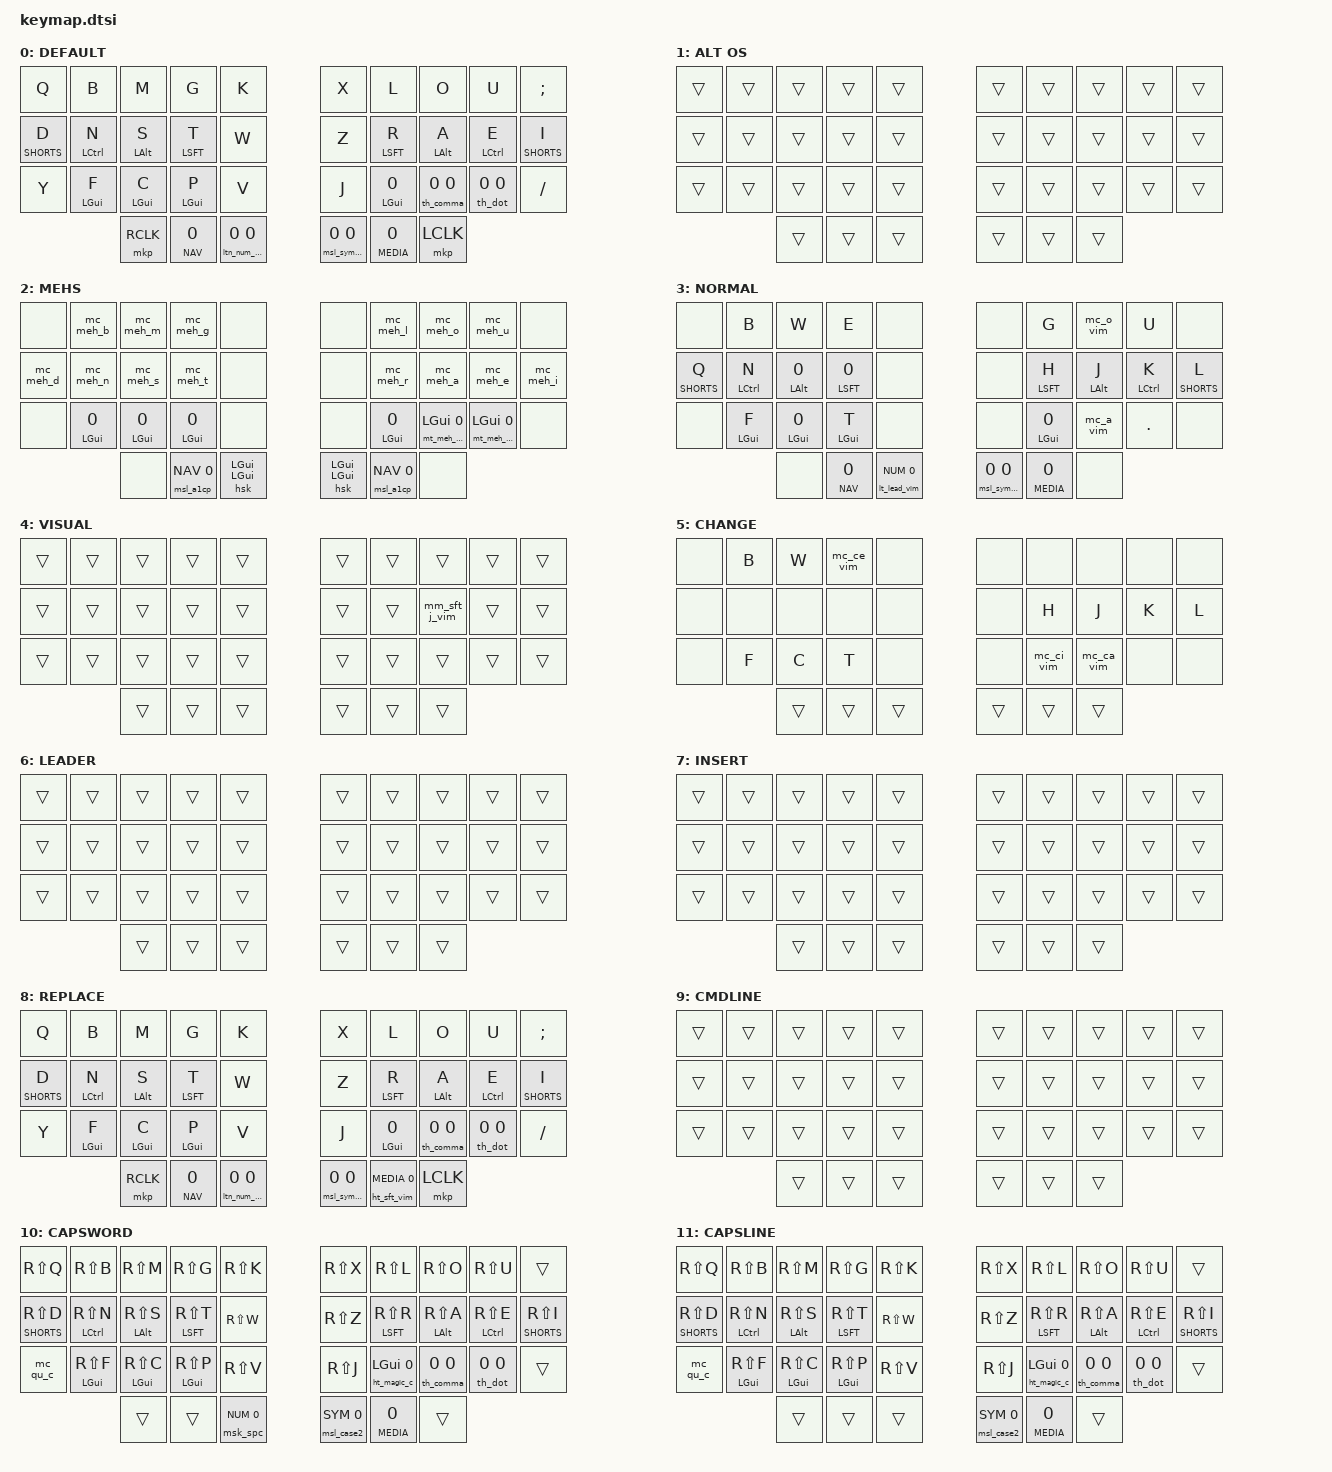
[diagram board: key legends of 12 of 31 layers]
/*
*
* Copyright (c) 2022 Rafael Romão
* SPDX-License-Identifier: MIT
*
*/

#include "includes.h"

/ {
        keymap {
                compatible = "zmk,keymap";

                default_layer {
                     display-name = "DEFAULT";
                     bindings = <
   &kp Q               &kp B               &kp M               &kp G               &kp K               &kp X               &kp L               &kp O               &kp U               &kp SEMICOLON
   &lt SHORTS D        &mt LCTL N          &mt LALT S          &mt LSFT T          &kp W               &kp Z               &mt LSFT R          &mt LALT A          &mt LCTL E          &lt SHORTS I
   &kp Y               &mt LGUI F          &mt LGUI C          &mt LGUI P          &kp V               &kp J               &ht_magic LGUI 0    &th_comma 0 0       &th_dot 0 0         &kp SLASH
                                           &mkp RCLK           &ht_repeat NAV 0    &ltn_num_spc 0 0    &msl_sym_a2 0 0     &ht_shift MEDIA 0   &mkp LCLK
                        >;
                };

                alt_os_layer {
                     display-name = "ALT OS";
                     bindings = <
   &trans              &trans              &trans              &trans              &trans              &trans              &trans              &trans              &trans              &trans    
   &trans              &trans              &trans              &trans              &trans              &trans              &trans              &trans              &trans              &trans  
   &trans              &trans              &trans              &trans              &trans              &trans              &trans              &trans              &trans              &trans 
                                           &trans              &trans              &trans              &trans              &trans              &trans
                        >;
                };


                mehs_layer {
                     display-name = "MEHS";
                     bindings = <
   &none              &mc_meh_b            &mc_meh_m           &mc_meh_g           &none               &none               &mc_meh_l           &mc_meh_o           &mc_meh_u           &none    
   &mc_meh_d          &mc_meh_n            &mc_meh_s           &mc_meh_t           &none               &none               &mc_meh_r           &mc_meh_a           &mc_meh_e           &mc_meh_i
   &none              &mt_meh_f LGUI 0     &mt_meh_c LGUI 0    &mt_meh_p LGUI 0    &none               &none               &mt_meh_h LGUI 0    &mt_meh_comm LGUI 0 &mt_meh_dot LGUI 0  &none
                                           &none               &msl_a1cp NAV 0     &hsk LGUI LGUI      &hsk LGUI LGUI      &msl_a1cp NAV 0     &none 
                        >;
                };


                vim_normal_layer {
                     display-name = "NORMAL";
                     bindings = <
   &none               &kp B               &kp W               &kp E               &none               &none               &kp G               &mc_o_vim           &kp U               &none
   &lt SHORTS Q        &mt LCTL N          &mt_s_vim LALT 0    &mt_r_vim LSFT 0    &none               &none               &mt LSFT H          &mt LALT J          &mt LCTL K          &lt SHORTS L
   &none               &mt LGUI F          &mt_c_vim LGUI 0    &mt LGUI T          &none               &none               &mt_i_vim LGUI 0    &mc_a_vim           &kp DOT             &none
                                           &none               &ht_repeat NAV 0    &lt_lead_vim NUM 0  &msl_sym_a2 0 0     &ht_shift MEDIA 0   &none
                        >;
                };

                vim_visual_layer {
                     display-name = "VISUAL";
                     bindings = <
   &trans              &trans              &trans              &trans              &trans              &trans              &trans              &trans              &trans              &trans    
   &trans              &trans              &trans              &trans              &trans              &trans              &trans              &mm_sft_j_vim       &trans              &trans  
   &trans              &trans              &trans              &trans              &trans              &trans              &trans              &trans              &trans              &trans 
                                           &trans              &trans              &trans              &trans              &trans              &trans
                        >;
                };

                vim_change_layer {
                     display-name = "CHANGE";
                     bindings = <
   &none               &kp B               &kp W               &mc_ce_vim          &none               &none               &none               &none               &none               &none
   &none               &none               &none               &none               &none               &none               &kp H               &kp J               &kp K               &kp L
   &none               &kp F               &kp C               &kp T               &none               &none               &mc_ci_vim          &mc_ca_vim          &none               &none
                                           &trans              &trans              &trans              &trans              &trans              &trans
                        >;
                };

                vim_leader_layer {
                     display-name = "LEADER";
                     bindings = <
   &trans              &trans              &trans              &trans              &trans              &trans              &trans              &trans              &trans              &trans    
   &trans              &trans              &trans              &trans              &trans              &trans              &trans              &trans              &trans              &trans  
   &trans              &trans              &trans              &trans              &trans              &trans              &trans              &trans              &trans              &trans 
                                           &trans              &trans              &trans              &trans              &trans              &trans
                        >;
                };

                vim_insert_layer {
                     display-name = "INSERT";
                     bindings = <
   &trans              &trans              &trans              &trans              &trans              &trans              &trans              &trans              &trans              &trans    
   &trans              &trans              &trans              &trans              &trans              &trans              &trans              &trans              &trans              &trans  
   &trans              &trans              &trans              &trans              &trans              &trans              &trans              &trans              &trans              &trans 
                                           &trans              &trans              &trans              &trans              &trans              &trans
                        >;
                };

                vim_replace_layer {
                     display-name = "REPLACE";
                     bindings = <
   &kp Q               &kp B               &kp M               &kp G               &kp K               &kp X               &kp L               &kp O               &kp U               &kp SEMICOLON
   &lt SHORTS D        &mt LCTL N          &mt LALT S          &mt LSFT T          &kp W               &kp Z               &mt LSFT R          &mt LALT A          &mt LCTL E          &lt SHORTS I
   &kp Y               &mt LGUI F          &mt LGUI C          &mt LGUI P          &kp V               &kp J               &ht_magic LGUI 0    &th_comma 0 0       &th_dot 0 0         &kp SLASH
                                           &mkp RCLK           &ht_repeat NAV 0    &ltn_num_spc 0 0    &msl_sym_a2 0 0     &ht_sft_vim MEDIA 0 &mkp LCLK
                        >;
                };

                vim_cmdline_layer {
                     display-name = "CMDLINE";
                     bindings = <
   &trans              &trans              &trans              &trans              &trans              &trans              &trans              &trans              &trans              &trans    
   &trans              &trans              &trans              &trans              &trans              &trans              &trans              &trans              &trans              &trans  
   &trans              &trans              &trans              &trans              &trans              &trans              &trans              &trans              &trans              &trans 
                                           &trans              &trans              &trans              &trans              &trans              &trans
                        >;
                };


                capsword_layer {
                     display-name = "CAPSWORD";
                     bindings = <
   &kp RS(Q)           &kp RS(B)           &kp RS(M)           &kp RS(G)           &kp RS(K)           &kp RS(X)           &kp RS(L)           &kp RS(O)           &kp RS(U)           &trans
   &lt SHORTS RS(D)    &mt LCTL RS(N)      &mt LALT RS(S)      &mt LSFT RS(T)      &kp RS(W)           &kp RS(Z)           &mt LSFT RS(R)      &mt LALT RS(A)      &mt LCTL RS(E)      &lt SHORTS RS(I) 
   &mc_qu_c            &mt LGUI RS(F)      &mt LGUI RS(C)      &mt LGUI RS(P)      &kp RS(V)           &kp RS(J)           &ht_magic_c LGUI 0  &th_comma 0 0       &th_dot 0 0         &trans
                                           &trans              &trans              &msk_spc NUM 0      &msl_case2 SYM 0    &lt_cancel MEDIA 0  &trans
                        >;
                };
                capsline_layer {
                     display-name = "CAPSLINE";
                     bindings = <
   &kp RS(Q)           &kp RS(B)           &kp RS(M)           &kp RS(G)           &kp RS(K)           &kp RS(X)           &kp RS(L)           &kp RS(O)           &kp RS(U)           &trans
   &lt SHORTS RS(D)    &mt LCTL RS(N)      &mt LALT RS(S)      &mt LSFT RS(T)      &kp RS(W)           &kp RS(Z)           &mt LSFT RS(R)      &mt LALT RS(A)      &mt LCTL RS(E)      &lt SHORTS RS(I) 
   &mc_qu_c            &mt LGUI RS(F)      &mt LGUI RS(C)      &mt LGUI RS(P)      &kp RS(V)           &kp RS(J)           &ht_magic_c LGUI 0  &th_comma 0 0       &th_dot 0 0         &trans
                                           &trans              &trans              &trans              &msl_case2 SYM 0    &lt_cancel MEDIA 0  &trans
                                           
                        >;
                };

                alpha2_layer {
                     display-name = "ALPHA2";
                     bindings = <
   &none               &kp Q               &mc_qu              &kp K               &none               &none               &ac_ocir            &ac_oacu            &ac_uacu            &none
   &kp Y               &kp Z               &kp X               &kp W               &none               &none               &ac_atil            &ac_aacu            &ac_eacu            &ac_iacu 
   &none               &kp J               &mc_ced             &reversed_magic     &none               &none               &ac_otil            &ac_acir            &ac_ecir            &none 
                                           &none               &mc_sqo             &kp UNDER           &kp SPACE           &mc_sqo             &none
                        >;
                };

                numbers_layer {
                     display-name = "NUMBERS";
                     bindings = <
   &none               &th_lbrc 0 0        &th_rbrc 0 0        &kp BSLH            &none               &none               &mc_n7              &mc_n8              &mc_n9              &none
   &lt_deg FUN 0       &th_lpar 0 0        &th_rpar 0 0        &kp AMPS            &none               &none               &mc_n4              &mc_n5              &mc_n6              &kp DOT  
   &none               &th_lbkt 0 0        &th_rbkt 0 0        &kp PIPE            &none               &none               &mc_n1              &mc_n2              &mc_n3              &none 
                                           &none               &trans              &trans              &hlt SYM SPACE      &lt_n0 MEDIA 0      &none 
                        >;
                };
                symbols_layer {
                     display-name = "SYMBOLS";
                     bindings = <
   &none               &mc_tilde           &kp HASH            &th_sqo 0 0         &none               &none               &th_perc 0 0        &th_eql 0 0         &th_colon_vim 0 0   &none
   &kp AT              &th_caret_z 0 0     &kp DOLLAR          &th_dqo 0 0         &none               &none               &th_qmark 0 0       &kp MINUS           &kp PLUS            &lt MACROS COMMA
   &none               &mc_lt              &mc_gt              &th_bti 0 0         &none               &none               &th_excl 0 0        &vim_slash          &kp STAR            &none 
                                           &none               &trans              &hlt NUM_CP SPACE   &none               &trans              &none        
                        >;
                };

                sentence_case_layer {
                     display-name = "SENTENCE CASE";
                     bindings = <
   &kp LS(Q)           &kp LS(B)           &kp LS(M)           &kp LS(G)           &kp LS(K)           &kp LS(X)           &kp LS(L)           &kp LS(O)           &kp LS(U)           &trans
   &kp LS(D)           &mt LCTL LS(N)      &mt LALT LS(S)      &mt LSFT LS(T)      &kp LS(W)           &kp LS(Z)           &mt LSFT LS(R)      &mt LALT LS(A)      &mt LCTL LS(E)      &kp LS(I) 
   &kp LS(Y)           &mt LGUI LS(F)      &mt LGUI LS(C)      &mt LGUI LS(P)      &kp LS(V)           &kp LS(J)           &ht_magic_c LGUI 0  &th_comma 0 0       &th_dot 0 0         &trans
                                           &trans              &trans              &trans              &lt_sft_a2 SYM_CP 0 &trans              &trans
                        >;
                };
                ccedil_layer {
                     display-name = "Ç EXTENSION";
                     bindings = <
   &none               &none               &none               &none               &none               &none               &none               &trans              &trans              &none     
   &none               &none               &none               &mc_aotil           &none               &none               &ac_atil            &trans              &none               &none   
   &none               &none               &none               &mc_otiles          &none               &none               &ac_otil            &trans              &trans              &none  
                                           &none               &sl ALPHA2          &trans              &trans              &trans              &none
                        >;
                };
                shifted_alpha2_layer {
                     display-name = "SHIFTED ALPHA2";
                     bindings = <
   &none               &kp LS(Q)           &mc_qu_s            &kp LS(K)           &none               &none               &ac_ocir_s          &ac_oacu_s          &ac_uacu_s          &none
   &kp LS(Y)           &kp LS(Z)           &kp LS(X)           &kp LS(W)           &none               &none               &ac_atil_s          &ac_aacu_s          &ac_eacu_s          &ac_iacu_s 
   &none               &kp LS(J)           &mc_ced_s           &reversed_magic_c   &none               &none               &ac_otil_s          &ac_acir_s          &ac_ecir_s          &none  
                                           &none               &mc_sqo             &trans              &kp SPACE           &mc_sqo             &none 
                        >;
                };
                case_alpha2_layer {
                     display-name = "CASE ALPHA2";
                     bindings = <
   &none               &kp RS(Q)           &mc_qu_c            &kp RS(K)           &none               &none               &ac_ocir_c          &ac_oacu_c          &ac_uacu_c          &none
   &kp RS(Y)           &kp RS(Z)           &kp RS(X)           &kp RS(W)           &none               &none               &ac_atil_c          &ac_aacu_c          &ac_eacu_c          &ac_iacu_c 
   &none               &kp RS(J)           &mc_ced_c           &reversed_magic_c   &none               &none               &ac_otil_c          &ac_acir_c          &ac_ecir_c          &none 
                                           &none               &mc_sqo             &kp UNDER           &kp SPACE           &mc_sqo             &none 
                        >;
                };
                case_ccedil_layer {
                     display-name = "CASE Ç EXTENSION";
                     bindings = <
   &none               &none               &none               &none               &none               &none               &none               &trans              &trans              &none     
   &none               &none               &none               &mc_aotil_c         &none               &none               &ac_atil_c          &trans              &none               &none   
   &none               &none               &none               &mc_otiles_c        &none               &none               &ac_otil_c          &trans              &trans              &none 
                                           &none               &sl CASE_A2         &trans              &trans              &trans              &none 
                        >;
                };


                shortcuts_layer {
                     display-name = "SHORTCUTS";
                     bindings = <
   &none              &mc_calc             &mc_files           &mc_browser         &none               &none               &mc_ai              &mc_editor          &mc_activities      &none    
   &mc_leader         &lt_zoom_out TOGS 0  &mc_zoom_in         &mc_reset_zoom      &none               &none               &tc_num_word        &mc_system          &lt_emoji TOGS 0    &mc_leader
   &none              &mc_close            &mc_refresh         &mc_reopen          &none               &none               &mc_screenshot      &mc_notes           &mc_term            &none 
                                           &none               &ht_repeat TEXT 0   &lt FUN SPACE       &lt MACROS SPACE    &ht_repeat TEXT 0   &none 
                        >;
                };
                toggles_layer {
                     display-name = "TOGGLES";
                     bindings = <
   &none              &kp CAPS             &to FUN             &to NAV             &none               &none               &to NAV             &to FUN             &kp CAPS            &none     
   &tog_off ALT_OS    &to ALT_OS           &to MEDIA           &to NUM             &none               &none               &to NUM             &to MEDIA           &to ALT_OS          &tog_off ALT_OS   
   &none              &kp KP_NUM           &to MEHS            &to VIM_NORMAL      &none               &none               &to VIM_NORMAL      &to MEHS            &kp KP_NUM          &none  
                                           &none               &mc_lock            &mc_sleep           &mc_lock            &mc_sleep           &none
                        >;
                };

                secondary_alternate_repeat_layer {
                     display-name = "ALT REP 2";
                     bindings = <
   &trans              &trans              &trans              &trans              &trans              &trans              &trans              &trans              &trans              &trans    
   &trans              &trans              &trans              &trans              &trans              &trans              &trans              &trans              &trans              &trans  
   &trans              &trans              &trans              &trans              &trans              &trans              &trans              &trans              &trans              &trans 
                                           &trans              &ht_alt_rep NAV 0   &trans              &trans              &trans              &trans
                        >;
                };

                navigation_layer {
                     display-name = "NAVIGATION";
                     bindings = <
   &none               &mc_swapper         &mc_tabs            &mc_launcher        &none               &none               &kp TAB             &lm_ent_vim         &lm_esc_vim         &none
   &lt TEXT INS        &kp LCTL            &kp LALT            &kp LSFT            &none               &none               &kp LEFT            &kp DOWN            &kp UP              &kp RIGHT
   &none               &kp LGUI            &kp LGUI            &kp LGUI            &none               &none               &kp DEL             &kp HOME            &kp END             &none 
                                           &none               &trans              &none               &hlt SYM_CP SPACE   &mo MEDIA           &none 
                        >;
                };

                numbers_copy_layer {
                     display-name = "NUMBERS";
                     bindings = <
   &none               &th_lbrc 0 0        &th_rbrc 0 0        &kp BSLH            &none               &none               &mc_n7              &mc_n8              &mc_n9              &none
   &mc_deg             &th_lpar 0 0        &th_rpar 0 0        &kp AMPS            &none               &none               &mc_n4              &mc_n5              &mc_n6              &kp DOT  
   &none               &th_lbkt 0 0        &th_rbkt 0 0        &kp PIPE            &none               &none               &mc_n1              &mc_n2              &mc_n3              &none 
                                           &none               &trans              &trans              &hlt SYM_CP SPACE   &lt_n0 MEDIA 0      &none 
                        >;
                };
                symbols_copy_layer {
                     display-name = "SYMBOLS";
                     bindings = <
   &none               &mc_tilde           &kp HASH            &th_sqo 0 0         &none               &none               &th_perc 0 0        &th_eql 0 0         &th_colon_vim 0 0   &none
   &kp AT              &th_caret_z 0 0     &kp DOLLAR          &th_dqo 0 0         &none               &none               &th_qmark 0 0       &kp MINUS           &kp PLUS            &kp STAR  
   &none               &mc_lt              &mc_gt              &th_bti 0 0         &none               &none               &th_excl 0 0        &kp SLASH           &kp STAR            &none 
                                           &none               &trans              &kp SPACE           &kp SPACE           &trans              &none 
                        >;
                };

                media_layer {
                    display-name = "MOUSE";
                    bindings = <
   &none               &mkp MCLK           &mkp LCLK           &mkp RCLK           &none               &none               &mc_home_tab        &mc_end_enter_vim   &lm_esc_vim        &none
   &none               &mmv MOVE_LEFT      &mmv MOVE_UP        &mmv MOVE_RIGHT     &none               &none               &mc_mic             &mt C_MUTE C_VOL_DN &kp C_VOL_UP       &lt_cam TEXT 0
   &none               &msc SCRL_DOWN      &mmv MOVE_DOWN      &msc SCRL_UP        &none               &none               &kp C_PP            &kp C_PREV          &kp C_NEXT         &none 
                                           &none               &mo NAV_CP          &kp SPACE           &none               &trans              &none 
                        >;
                };
                navigation_copy_layer {
                     display-name = "NAVIGATION";
                     bindings = <
   &none               &mc_swapper         &mc_tabs            &mc_launcher        &none               &none               &kp TAB             &lm_ent_vim         &lm_esc_vim        &none
   &kp INS             &kp LCTL            &kp LALT            &kp LSFT            &none               &none               &kp LEFT            &kp DOWN            &kp UP             &kp RIGHT
   &none               &kp LGUI            &kp LGUI            &kp LGUI            &none               &none               &kp DEL             &kp HOME            &kp END            &none 
                                           &none               &trans              &trans              &trans              &trans              &none 
                        >;
                };

                text_layer {
                     display-name = "TEXT NAVIGATION";
                     bindings = <
   &none               &select_home        &select_word        &select_line        &trans              &trans              &kp TAB             &lm_ent_vim         &lm_esc_vim        &none
   &none               &hsk LCTL RCTL      &hsk LALT RALT      &hsk LSFT RSFT      &trans              &trans              &mc_prev_word       &kp DOWN            &kp UP             &mc_next_word
   &none               &hsk LGUI RGUI      &hsk LGUI RGUI      &hsk LGUI RGUI      &trans              &trans              &mc_del_word        &kp HOME            &kp END            &none 
                                           &none               &key_repeat         &none               &none               &key_repeat         &none 
                        >;
                };
                functions_layer {
                     display-name = "FUNCTIONS";
                     bindings = <
   &none               &bt BT_PRV          &bt BT_NXT          &bt BT_SEL 0        &none               &none               &kp F7              &kp F8              &kp F9             &none 
   &none               &hsk RCTL LCTL      &hsk RALT LALT      &hsk RSFT LSFT      &none               &none               &kp F4              &kp F5              &kp F6             &none      
   &none               &hsk RGUI LGUI      &hsk RGUI LGUI      &hsk RGUI LGUI      &none               &none               &kp F1              &kp F2              &kp F3             &none
                                           &none               &bootloader         &none               &none               &key_repeat         &none
                        >;
                };


                macros_layer {
                     display-name = "MACROS";
                     bindings = <
   &none               &mc_tisl            &mc_ds              &mc_dds             &none               &none               &mc_colpercsslash   &mc_o_esc           &mc_sft_o_esc     &none 
   &mc_exit            &mc_hugs            &mc_oref            &mc_otask           &none               &none               &lm_sft_v_vim       &mc_dqt0p           &mc_dqt1p         &none
   &none               &lm_os              &mc_comment         &mc_haha            &none               &none               &lm_ctl_v_vim       &mc_dqtplusp        &mc_dqtplusy      &none
                                           &none               &key_repeat         &mc_spc_esc         &none               &bootloader         &none
                        >;
                };


        };
};
